AUTOSAR XML (schema 00050)
package /ComponentTypes
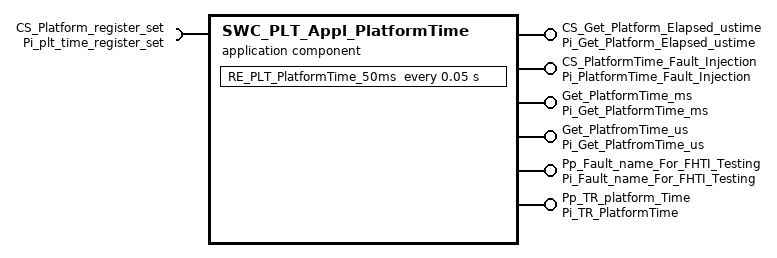
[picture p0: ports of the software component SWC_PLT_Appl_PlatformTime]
  application sw component type SWC_PLT_Appl_PlatformTime
    6 x provide port:
      CS_Get_Platform_Elapsed_ustime: server-com-spec{operation=read, queue-length=1}, provided-interface=Pi_Get_Platform_Elapsed_ustime
      CS_PlatformTime_Fault_Injection: server-com-spec{operation=Read, queue-length=1}, provided-interface=Pi_PlatformTime_Fault_Injection
      Get_PlatformTime_ms: server-com-spec{operation=read, queue-length=1}, provided-interface=Pi_Get_PlatformTime_ms
      Get_PlatfromTime_us: server-com-spec{operation=read, queue-length=1}, provided-interface=Pi_Get_PlatfromTime_us
      Pp_Fault_name_For_FHTI_Testing: nonqueued-sender-com-spec{data-element=De_Fault_name_FHTI, init-value=0}, provided-interface=Pi_Fault_name_For_FHTI_Testing
      Pp_TR_platform_Time: nonqueued-sender-com-spec{data-element=De_PlatformTime, init-value=85}, provided-interface=Pi_TR_PlatformTime
    require port CS_Platform_register_set: client-com-spec=fault_type, required-interface=Pi_plt_time_register_set
    behavior SWC_PLT_Appl_PlatformTime_InternalBehavior
      exclusive area PlatformTime_ExclusiveArea
      4 x operation invoked event:
        OIT_CS_Get_Platform_Elapsed_ustime_read_CS_Get_Platform_Elapsed_ustime_read: start-on-event=CS_Get_Platform_Elapsed_ustime_read, operation=CS_Get_Platform_Elapsed_ustime.read
        OIT_CS_PlatformTime_Fault_Injection_Read_CS_PlatformTime_Fault_Injection_Read: start-on-event=CS_PlatformTime_Fault_Injection, operation=CS_PlatformTime_Fault_Injection.Read
        OIT_Get_PlatformTime_ms_read_Get_PlatformTime_ms_read: start-on-event=Get_PlatformTime_ms_read, operation=Get_PlatformTime_ms.read
        OIT_Get_PlatfromTime_us_read_Get_PlatfromTime_us_read: start-on-event=Get_PlatfromTime_us_read, operation=Get_PlatfromTime_us.read
      init event SWC_PLT_Appl_PlatformTime_InitEvent: start-on-event=RE_Evaluate_Plt_Time_Init
      timing event TMT_RE_PLT_PlatformTime_50ms: start-on-event=RE_PLT_PlatformTime_50ms, period=0.05
      init event RE_PLT_PlatformTime_InitEvent: start-on-event=RE_PLT_PlatformTime_Init
      7 x runnable:
        CS_Get_Platform_Elapsed_ustime_read: can-be-invoked-concurrently=true
        CS_PlatformTime_Fault_Injection
        Get_PlatformTime_ms_read: can-enter-exclusive-area=PlatformTime_ExclusiveArea, can-be-invoked-concurrently=true
        Get_PlatfromTime_us_read: can-enter-exclusive-area=PlatformTime_ExclusiveArea, can-be-invoked-concurrently=true
          sync call SC_CS_Platform_register_set_Operation: operation=CS_Platform_register_set.fault_type
        RE_Evaluate_Plt_Time_Init
          data-send-points:
            access SEND_Pp_TR_PlatformTime_De_TR_PlatformTime: accessed-variable=Pp_TR_platform_Time.De_PlatformTime
        RE_PLT_PlatformTime_50ms
        RE_PLT_PlatformTime_Init
          data-send-points:
            access SEND_Pp_Fault_name_For_FHTI_Testing_De_Fault_name_FHTI: accessed-variable=Pp_Fault_name_For_FHTI_Testing.De_Fault_name_FHTI
  swc implementation SWC_PLT_Appl_PlatformTime_Implementation: behavior=SWC_PLT_Appl_PlatformTime_InternalBehavior
    code-descriptors:
      code Default: artifact-descriptors=autosar-engineering-object=category=SWSRC
